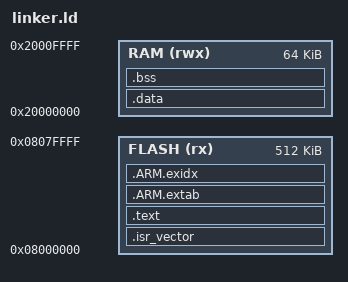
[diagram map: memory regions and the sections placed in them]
/* Minimal linker script for Cortex-M4 MCU (example: STM32F303RE) */

MEMORY
{
    FLASH (rx)  : ORIGIN = 0x08000000, LENGTH = 512K
    RAM   (rwx) : ORIGIN = 0x20000000, LENGTH = 64K
}

_estack = ORIGIN(RAM) + LENGTH(RAM);

SECTIONS
{
    .isr_vector :
    {
        KEEP(*(.isr_vector))
    } > FLASH

    .text :
    {
        *(.text*)
        *(.rodata*)
        *(.glue_7)
        *(.glue_7t)
        KEEP(*(.init))
        KEEP(*(.fini))
    } > FLASH

    .ARM.extab : { *(.ARM.extab* .gnu.linkonce.armextab.*) } > FLASH
    .ARM.exidx : { *(.ARM.exidx* .gnu.linkonce.armexidx.*) } > FLASH

    .data : AT (ADDR(.text) + SIZEOF(.text))
    {
        _sidata = LOADADDR(.data);
        _sdata = .;
        *(.data*)
        _edata = .;
    } > RAM

    .bss :
    {
        _sbss = .;
        *(.bss*)
        *(COMMON)
        _ebss = .;
    } > RAM

    . = ALIGN(4);
    end = .;
    PROVIDE(_end = .);
}
